# AT32F437xx_v2 register map
Vendor: Keil; Series: AT32F437; File version: 1.0
CPU: CM4 r0p1, little endian, no MPU, FPU, 4 interrupt priority bits
Registers are 32-bit, read-write, reset 0x0 unless marked. A register's access mark holds for its fields unless they carry their own. Offsets are from the block's base; [hi:lo] are bit positions; {n}, {i} and the like mark numbered series; 'fields as' and 'values as' point back to an identical list.

## DMA1 — DMA controller
Base 0x40026400
Same registers: DMA2 0x40026600
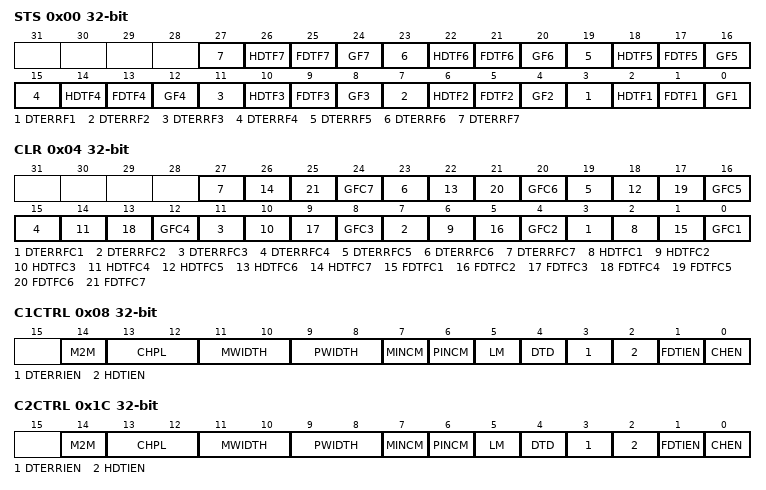
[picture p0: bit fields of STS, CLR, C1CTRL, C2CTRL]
0x00 STS ro — DMA interrupt status register (DMA_STS)
  [4n-1] DTERRF{n} (n=1..7) — Channel {n} data transfer error event flag
  [4n-2] HDTF{n} (n=1..7) — Channel {n} half data transfer event flag
  [4n-3] FDTF{n} (n=1..7) — Channel {n} full data transfer event flag
  [4n-4] GF{n} (n=1..7) — Channel {n} Global event flag
0x04 CLR — DMA interrupt flag clear register (DMA_CLR)
  [4n-1] DTERRFC{n} (n=1..7) — Channel {n} data transfer error flag clear
  [4n-2] HDTFC{n} (n=1..7) — Channel {n} half data transfer flag clear
  [4n-3] FDTFC{n} (n=1..7) — Channel {n} full data transfer flag clear
  [4n-4] GFC{n} (n=1..7) — Channel {n} Global flag clear
0x08 C1CTRL — DMA channel configuration register(DMA_C1CTRL)
  [14] M2M — Memory to memory mode
  [13:12] CHPL — Channel Priority level
  [11:10] MWIDTH — Memory data bit width
  [9:8] PWIDTH — Peripheral data bit width
  [7] MINCM — Memory increment mode
  [6] PINCM — Peripheral increment mode
  [5] LM — Loop mode
  [4] DTD — Data transfer direction
  [3] DTERRIEN — Transfer error interrupt enable
  [2] HDTIEN — Half transfer interrupt enable
  [1] FDTIEN — Transfer complete interrupt enable
  [0] CHEN — Channel enable
0x0C C1DTCNT — DMA channel 1 number of data to transfer register
  [15:0] CNT — Number of data to transfer
0x10 C1PADDR — DMA channel 1 peripheral base address register
  [31:0] PADDR — Peripheral address
{0x0+0x14*i} C{i}MADDR (i=1..5) — DMA channel {i} memory base address register
  [31:0] MADDR — Memory address
0x1C C2CTRL — DMA channel configuration register (DMA_C2CTRL)
  fields as C1CTRL
0x20 C2DTCNT — DMA channel 2 number of data to transferregister
  [15:0] CNT — Number of data to transfer
0x24 C2PADDR — DMA channel 2 peripheral base address register
  [31:0] PADDR — Peripheral address
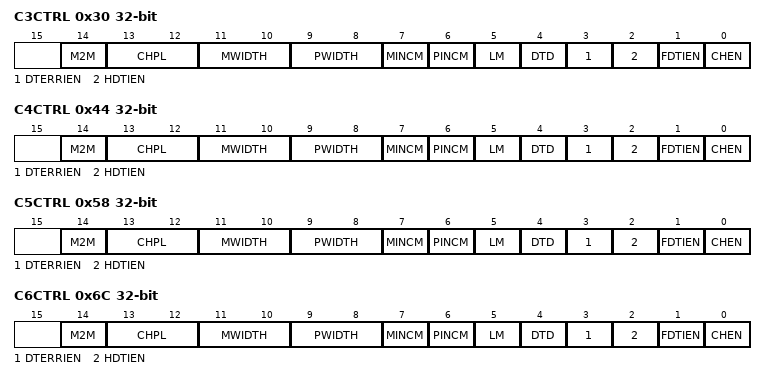
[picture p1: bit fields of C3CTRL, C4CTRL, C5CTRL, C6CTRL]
0x30 C3CTRL — DMA channel configuration register (DMA_C3CTRL)
  fields as C1CTRL
0x34 C3DTCNT — DMA channel 3 number of data to transfer register
  [15:0] CNT — Number of data to transfer
0x38 C3PADDR — DMA channel 3 peripheral base address register
  [31:0] PADDR — Peripheral address
0x44 C4CTRL — DMA channel configuration register (DMA_C4CTRL)
  fields as C1CTRL
0x48 C4DTCNT — DMA channel 4 number of data to transfer register
  [15:0] CNT — Number of data to transfer
0x4C C4PADDR — DMA channel 4 peripheral base address register
  [31:0] PADDR — Peripheral address
0x58 C5CTRL — DMA channel configuration register (DMA_C5CTRL)
  fields as C1CTRL
0x5C C5DTCNT — DMA channel 5 number of data to transfer register
  [15:0] CNT — Number of data to transfer
0x60 C5PADDR — DMA channel 5 peripheral base address register
  [31:0] PADDR — Peripheral address
0x6C C6CTRL — DMA channel configuration register(DMA_C6CTRL)
  fields as C1CTRL
0x70 C6DTCNT — DMA channel 6 number of data to transfer register
  [15:0] CNT — Number of data to transfer
0x74 C6PADDR — DMA channel 6 peripheral address base register
  [31:0] PADDR — Peripheral address
0x78 C6MADDR — DMA channel 6 memory address base register
  [31:0] MADDR — Memory address
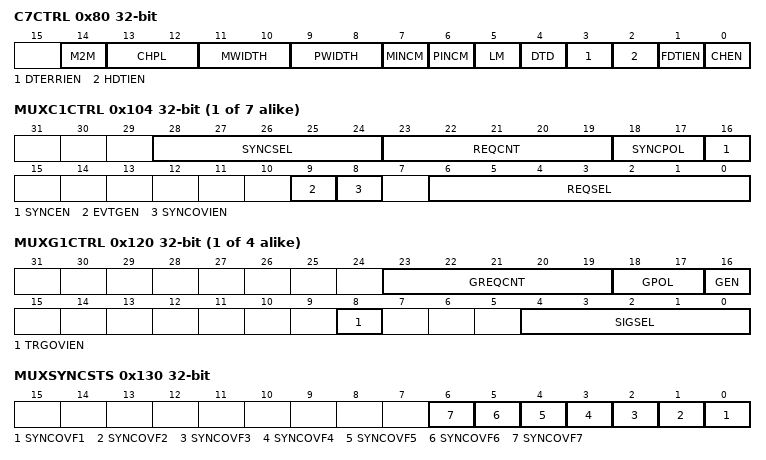
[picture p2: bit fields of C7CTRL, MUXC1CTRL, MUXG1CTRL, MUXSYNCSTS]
0x80 C7CTRL — DMA channel configuration register(DMA_C7CTRL)
  fields as C1CTRL
0x84 C7DTCNT — DMA channel 7 number of data to transfer register
  [15:0] CNT — Number of data to transfer
0x88 C7PADDR — DMA channel 7 peripheral base address register
  [31:0] PADDR — Peripheral address
0x8C C7MADDR — DMA channel 7 memory base address register
  [31:0] MADDR — Memory address
0x100 DMA_MUXSEL — DMAMUX Table Selection
  [0] TBL_SEL — Multiplexer Table Select
{0x100+4i} MUXC{i}CTRL (i=1..7) — Channel {i} Configuration Register
  [28:24] SYNCSEL — Synchronization Identification
  [23:19] REQCNT — Number of DMA requests
  [18:17] SYNCPOL — Synchronization polarity
  [16] SYNCEN — Synchroniztion enable
  [9] EVTGEN — Event generation enable
  [8] SYNCOVIEN — Synchronization overrun interrupt enable
  [6:0] REQSEL — DMA request select
{0x11C+4i} MUXG{i}CTRL (i=1..4) — Generator {i} Configuration Register
  [23:19] GREQCNT — Number of DMA requests to be generated
  [18:17] GPOL — DMA request generator trigger polarity
  [16] GEN — DMA request generator enable
  [8] TRGOVIEN — Trigger overrun interrupt enable
  [4:0] SIGSEL — Signal select
0x130 MUXSYNCSTS — Channel Interrupt Status Register
  [n-1] SYNCOVF{n} ro (n=1..7) — Synchronizaton overrun interrupt flag
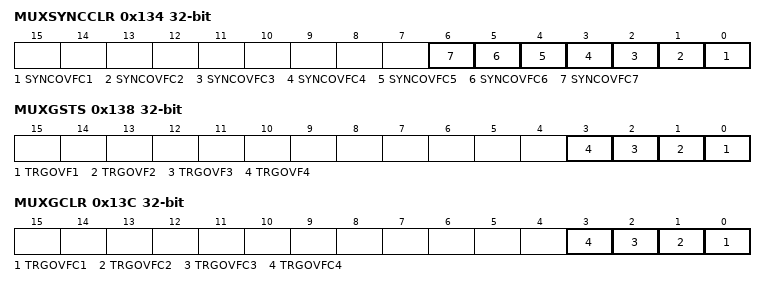
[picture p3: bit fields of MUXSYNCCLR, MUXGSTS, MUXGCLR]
0x134 MUXSYNCCLR — Channel Interrupt Clear Flag Register
  [n-1] SYNCOVFC{n} (n=1..7) — Clear synchronizaton overrun interrupt flag
0x138 MUXGSTS — Generator Interrupt Status Register
  [n-1] TRGOVF{n} (n=1..4) — Trigger overrun interrupt flag
0x13C MUXGCLR — Generator Interrupt Clear Flag Register
  [n-1] TRGOVFC{n} (n=1..4) — Clear trigger overrun interrupt flag
